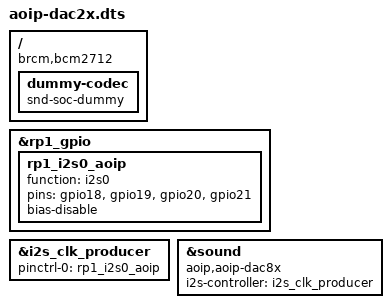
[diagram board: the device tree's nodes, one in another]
/dts-v1/;
/plugin/;

/*
 * AoIP DAC2x + ADC2x Device Tree Overlay — I2S Master Mode (2채널)
 * compatible: aoip,aoip-dac8x  (기존 커널 모듈 of_match 재사용 → 모듈 재빌드 불필요)
 * RPi(CM5)가 I2S clock producer(master) → RPi가 BCK/LRCLK 생성
 * i2s_clk_producer = RP1 i2s@a0000 (I2S0 하드웨어 블록)
 *
 * 8채널(aoip-dac8x) 대비 핀 맵 차이:
 *   - I2S0 로 GPIO18~21 4핀만 먹스 (BCK/LRCLK + 데이터 1쌍)
 *       gpio18 = I2S0 SCLK  (BCK)
 *       gpio19 = I2S0 WS    (LRCLK)
 *       gpio20 = I2S0 SDI0  (capture / ADC 입력)
 *       gpio21 = I2S0 SDO0  (playback / DAC 출력)
 *   - GPIO22~27 은 I2S 에서 해제 → 실제 회로의 다른 용도와 핀 충돌 방지
 */

/ {
	compatible = "brcm,bcm2712";

	fragment@0 {
		target = <&rp1_gpio>;
		__overlay__ {
			rp1_i2s0_aoip: rp1_i2s0_aoip {
				function = "i2s0";
				pins = "gpio18", "gpio19", "gpio20", "gpio21";
				bias-disable;
				status = "okay";
			};
		};
	};

	fragment@1 {
		target = <&i2s_clk_producer>;
		__overlay__ {
			pinctrl-names = "default";
			pinctrl-0 = <&rp1_i2s0_aoip>;
			status = "okay";
		};
	};

	fragment@2 {
		target-path = "/";
		__overlay__ {
			dummy-codec {
				#sound-dai-cells = <0>;
				compatible = "snd-soc-dummy";
				status = "okay";
			};
		};
	};

	fragment@3 {
		target = <&sound>;
		__overlay__ {
			compatible = "aoip,aoip-dac8x";
			i2s-controller = <&i2s_clk_producer>;
			status = "okay";
		};
	};
};
